CM_ "IMPORT _toyota_2017.dbc"
CM_ "IMPORT _comma.dbc"

BO_ 548 BRAKE_MODULE: 8 XXX
 SG_ BRAKE_PRESSURE : 43|12@0+ (1,0) [0|4047] "" XXX
 SG_ BRAKE_PRESSED : 5|1@0+ (1,0) [0|1] "" XXX

BO_ 705 GAS_PEDAL: 8 XXX
 SG_ GAS_RELEASED : 3|1@0+ (1,0) [0|1] "" XXX
 SG_ GAS_PEDAL : 55|8@0+ (0.005,0) [0|1] "" XXX

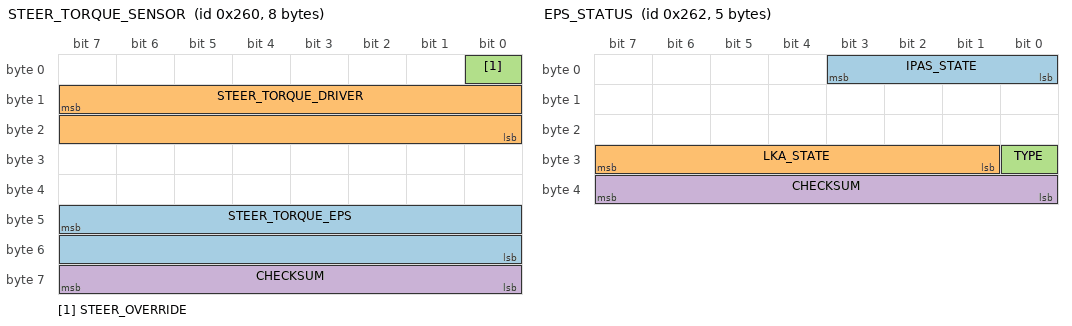
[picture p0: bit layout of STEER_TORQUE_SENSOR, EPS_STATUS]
BO_ 608 STEER_TORQUE_SENSOR: 8 XXX
 SG_ STEER_TORQUE_EPS : 47|16@0- (1.0,0) [-20000|20000] "" XXX
 SG_ STEER_TORQUE_DRIVER : 15|16@0- (1,0) [-32768|32767] "" XXX
 SG_ STEER_OVERRIDE : 0|1@0+ (1,0) [0|1] "" XXX
 SG_ CHECKSUM : 63|8@0+ (1,0) [0|255] "" XXX

BO_ 610 EPS_STATUS: 5 EPS
 SG_ IPAS_STATE : 3|4@0+ (1,0) [0|15] "" XXX
 SG_ LKA_STATE : 31|7@0+ (1,0) [0|127] "" XXX
 SG_ TYPE : 24|1@0+ (1,0) [0|1] "" XXX
 SG_ CHECKSUM : 39|8@0+ (1,0) [0|255] "" XXX

BO_ 956 GEAR_PACKET: 8 XXX
 SG_ GEAR : 13|6@0+ (1,0) [0|63] "" XXX

CM_ SG_ 548 BRAKE_PRESSURE "seems prop to pedal force";
CM_ SG_ 548 BRAKE_POSITION "seems proportional to pedal displacement, unclear the max value of 0x1c8";
CM_ SG_ 610 TYPE "seems 1 on Corolla, 0 on all others";
VAL_ 956 GEAR 0 "D" 1 "S" 8 "N" 16 "R" 32 "P";
VAL_ 610 IPAS_STATE 5 "override" 3 "enabled" 1 "disabled";
VAL_ 610 LKA_STATE 25 "temporary_fault" 9 "temporary_fault2" 5 "active" 1 "standby";

BO_ 512 GAS_COMMAND: 6 EON
 SG_ GAS_COMMAND : 7|16@0+ (0.253984064,-83.3) [0|1] "" INTERCEPTOR
 SG_ GAS_COMMAND2 : 23|16@0+ (0.126992032,-83.3) [0|1] "" INTERCEPTOR
 SG_ ENABLE : 39|1@0+ (1,0) [0|1] "" INTERCEPTOR
 SG_ CHECKSUM : 43|8@0+ (1,0) [0|3] "" INTERCEPTOR

BO_ 513 GAS_SENSOR: 6 INTERCEPTOR
 SG_ INTERCEPTOR_GAS : 7|16@0+ (0.253984064,-83.3) [0|1] "" EON
 SG_ INTERCEPTOR_GAS2 : 23|16@0+ (0.126992032,-83.3) [0|1] "" EON
 SG_ STATE : 39|8@0+ (1,0) [0|255] "" EON
 SG_ CHECKSUM : 43|8@0+ (1,0) [0|3] "" EON

VAL_ 513 STATE 5 "FAULT_TIMEOUT" 4 "FAULT_STARTUP" 3 "FAULT_SCE" 2 "FAULT_SEND" 1 "FAULT_BAD_CHECKSUM" 0 "NO_FAULT" ;
